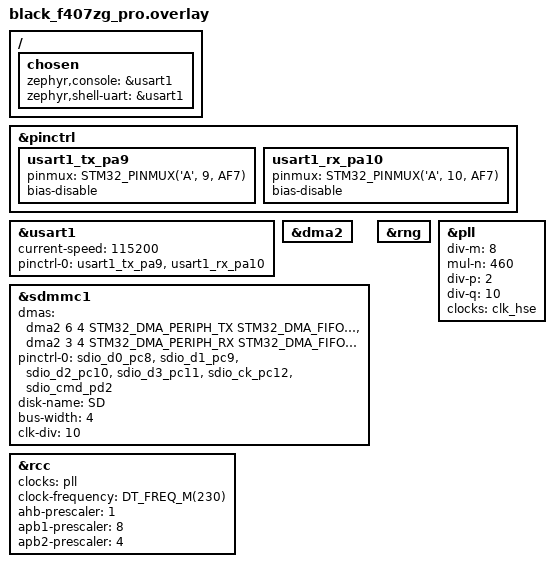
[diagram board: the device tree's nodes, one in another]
/*
 * Board overlay: route the Zephyr console to USART1 (PA9/PA10).
 *
 * The RT-Thread Spark board wires its ST-LINK V2.1 virtual COM port to
 * USART1, but the upstream black_f407zg_pro board defaults the Zephyr
 * console to USART2 (PA2/PA3). Without this overlay, all printk output
 * (including the ES8388 codec diagnostics) is sent to an unconnected UART.
 */

/ {
	chosen {
		zephyr,console = &usart1;
		zephyr,shell-uart = &usart1;
	};
};

&pinctrl {
	usart1_tx_pa9: usart1_tx_pa9 {
		pinmux = <STM32_PINMUX('A', 9, AF7)>;
		bias-disable;
	};

	usart1_rx_pa10: usart1_rx_pa10 {
		pinmux = <STM32_PINMUX('A', 10, AF7)>;
		bias-disable;
	};
};

&usart1 {
	status = "okay";
	current-speed = <115200>;
	pinctrl-0 = <&usart1_tx_pa9 &usart1_rx_pa10>;
	pinctrl-names = "default";
};

&dma2 {
	status = "okay";
};

&sdmmc1 {
	status = "okay";
	/* SDIO is served by DMA2 streams 3/6 on channel 4. */
	dmas = <&dma2 6 4 STM32_DMA_PERIPH_TX STM32_DMA_FIFO_FULL>,
	       <&dma2 3 4 STM32_DMA_PERIPH_RX STM32_DMA_FIFO_FULL>;
	dma-names = "tx", "rx";
	pinctrl-0 = <&sdio_d0_pc8 &sdio_d1_pc9 &sdio_d2_pc10 &sdio_d3_pc11 &sdio_ck_pc12 &sdio_cmd_pd2>;
	pinctrl-names = "default";
	disk-name = "SD";
	bus-width = <4>;
	/* F4 has no SDIO hardware flow control; 48 MHz / (10 + 2) = 4 MHz avoids RX FIFO overrun. */
	clk-div = <10>;
};

&rng {
	status = "okay";
};

/* Overclock STM32F407 to 230 MHz:
 * HSE = 8 MHz / M(8) = 1 MHz * N(460) = 460 MHz VCO
 * SYSCLK = 460 MHz / P(2) = 230 MHz
 * PLL48CK = 460 MHz / Q(10) = 46.0 MHz (SDIO & RNG)
 * AHB = 230 MHz, APB1 = 28.75 MHz (<= 42 MHz max), APB2 = 57.5 MHz (<= 84 MHz max)
 */
&pll {
	div-m = <8>;
	mul-n = <460>;
	div-p = <2>;
	div-q = <10>;
	clocks = <&clk_hse>;
	status = "okay";
};

&rcc {
	clocks = <&pll>;
	clock-frequency = <DT_FREQ_M(230)>;
	ahb-prescaler = <1>;
	apb1-prescaler = <8>;
	apb2-prescaler = <4>;
};

